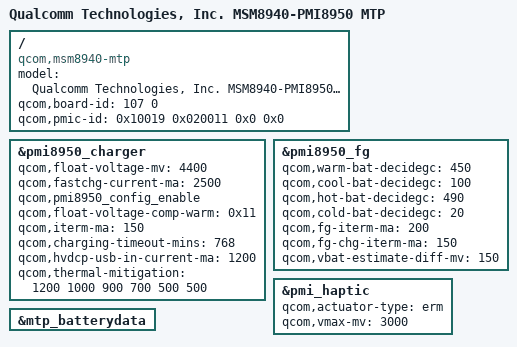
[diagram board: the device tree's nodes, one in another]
/*
 * Copyright (c) 2016, The Linux Foundation. All rights reserved.
 *
 * This program is free software; you can redistribute it and/or modify
 * it under the terms of the GNU General Public License version 2 and
 * only version 2 as published by the Free Software Foundation.
 *
 * This program is distributed in the hope that it will be useful,
 * but WITHOUT ANY WARRANTY; without even the implied warranty of
 * MERCHANTABILITY or FITNESS FOR A PARTICULAR PURPOSE.  See the
 * GNU General Public License for more details.
 */

/dts-v1/;

#include "msm8940.dtsi"
#include "msm8940-pmi8950-mtp.dtsi"
#include "zte-msm8940-pmi8950-daphne.dtsi"
#include "msm8940-camera-sensor-zte-daphne.dtsi"


/ {
	model = "Qualcomm Technologies, Inc. MSM8940-PMI8950 MTP";
	compatible = "qcom,msm8940-mtp", "qcom,msm8940", "qcom,mtp";
	qcom,board-id= <107 0>;
	qcom,pmic-id = <0x10019 0x020011 0x0 0x0>;
};


&pmi8950_charger {
	qcom,float-voltage-mv = <4400>;
	qcom,fastchg-current-ma = <2500>;
	qcom,pmi8950_config_enable;
	qcom,float-voltage-comp-warm = <0x11>;
	qcom,iterm-ma = <150>;
	qcom,charging-timeout-mins = <768>;
	qcom,hvdcp-usb-in-current-ma = <1200>;
	qcom,thermal-mitigation = <1200 1000 900 700 500 500>;
};
&pmi8950_fg{
	qcom,warm-bat-decidegc = <450>;
	qcom,cool-bat-decidegc = <100>;
	qcom,hot-bat-decidegc = <490>;
	qcom,cold-bat-decidegc = <20>;
	qcom,fg-iterm-ma = <200>;
	qcom,fg-chg-iterm-ma = <150>;
	qcom,vbat-estimate-diff-mv = <150>;
};
&pmi_haptic{
	qcom,actuator-type = "erm";
	qcom,vmax-mv = <3000>;
};
&mtp_batterydata {
	#include "zte_z610dl_3900mAh.dtsi"
};
